AUTOSAR XML (schema 4-0-3)
package /ComponentTypes
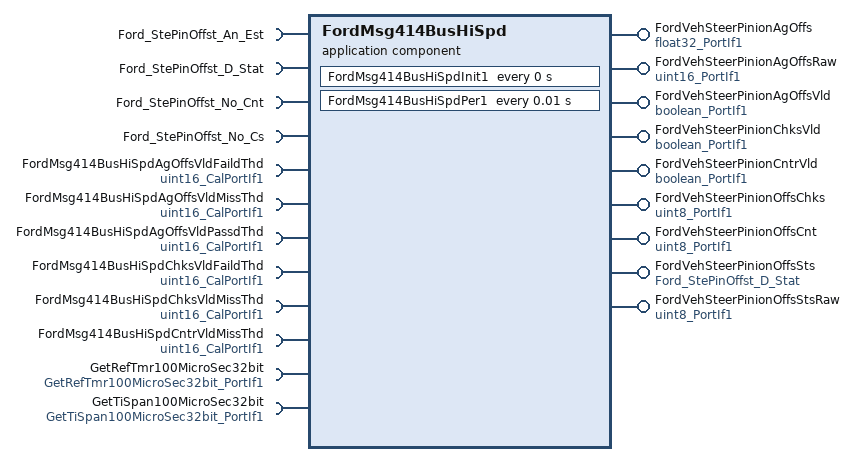
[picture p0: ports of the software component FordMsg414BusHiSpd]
  application sw component type FordMsg414BusHiSpd
    9 x provide port:
      FordVehSteerPinionAgOffs: nonqueued-sender-com-spec{data-element=Val, init-value=0}, provided-interface=float32_PortIf1
      FordVehSteerPinionAgOffsRaw: nonqueued-sender-com-spec{data-element=Val, init-value=32000}, provided-interface=uint16_PortIf1
      FordVehSteerPinionAgOffsVld: nonqueued-sender-com-spec{data-element=Logl, init-value=0}, provided-interface=boolean_PortIf1
      FordVehSteerPinionChksVld: nonqueued-sender-com-spec{data-element=Logl, init-value=0}, provided-interface=boolean_PortIf1
      FordVehSteerPinionCntrVld: nonqueued-sender-com-spec{data-element=Logl, init-value=0}, provided-interface=boolean_PortIf1
      FordVehSteerPinionOffsChks: nonqueued-sender-com-spec{data-element=Val, init-value=0}, provided-interface=uint8_PortIf1
      FordVehSteerPinionOffsCnt: nonqueued-sender-com-spec{data-element=Val, init-value=0}, provided-interface=uint8_PortIf1
      FordVehSteerPinionOffsSts: nonqueued-sender-com-spec{data-element=Ford_StePinOffst_D_Stat, init-value=0}, provided-interface=Ford_StePinOffst_D_Stat
      FordVehSteerPinionOffsStsRaw: nonqueued-sender-com-spec{data-element=Val, init-value=0}, provided-interface=uint8_PortIf1
    12 x require port:
      Ford_StePinOffst_An_Est: nonqueued-receiver-com-spec{data-element=Ford_StePinOffst_An_Est, filter=data-filter-type=ALWAYS, init-value=32000}, required-interface=Ford_StePinOffst_An_Est
      Ford_StePinOffst_D_Stat: nonqueued-receiver-com-spec{data-element=Ford_StePinOffst_D_Stat, filter=data-filter-type=ALWAYS, init-value=0}, required-interface=Ford_StePinOffst_D_Stat
      Ford_StePinOffst_No_Cnt: nonqueued-receiver-com-spec{data-element=Ford_StePinOffst_No_Cnt, filter=data-filter-type=ALWAYS, init-value=0}, required-interface=Ford_StePinOffst_No_Cnt
      Ford_StePinOffst_No_Cs: nonqueued-receiver-com-spec{data-element=Ford_StePinOffst_No_Cs, filter=data-filter-type=ALWAYS, init-value=0}, required-interface=Ford_StePinOffst_No_Cs
      FordMsg414BusHiSpdAgOffsVldFaildThd: parameter-require-com-spec{init-value=0, parameter=Val}, required-interface=uint16_CalPortIf1
      FordMsg414BusHiSpdAgOffsVldMissThd: parameter-require-com-spec{init-value=1000, parameter=Val}, required-interface=uint16_CalPortIf1
      FordMsg414BusHiSpdAgOffsVldPassdThd: parameter-require-com-spec{init-value=0, parameter=Val}, required-interface=uint16_CalPortIf1
      FordMsg414BusHiSpdChksVldFaildThd: parameter-require-com-spec{init-value=0, parameter=Val}, required-interface=uint16_CalPortIf1
      FordMsg414BusHiSpdChksVldMissThd: parameter-require-com-spec{init-value=0, parameter=Val}, required-interface=uint16_CalPortIf1
      FordMsg414BusHiSpdCntrVldMissThd: parameter-require-com-spec{init-value=0, parameter=Val}, required-interface=uint16_CalPortIf1
      GetRefTmr100MicroSec32bit: client-com-spec=Oper, required-interface=GetRefTmr100MicroSec32bit_PortIf1
      GetTiSpan100MicroSec32bit: client-com-spec=Oper, required-interface=GetTiSpan100MicroSec32bit_PortIf1
    behavior FordMsg414BusHiSpd_InternalBehavior
      ar-typed-per-instance-memorys:
        17 x data, all with sw-calibration-access=READ-ONLY:
          AgOffsVldFaildRefTi: type=uint32
          AgOffsVldMissRefTi: type=uint32
          AgOffsVldPassdRefTi: type=uint32
          ChksVldFaildRefTi: type=uint32
          ChksVldMissRefTi: type=uint32
          CntrVldMissRefTi: type=uint32
          FirstTranVldFlg: type=boolean
          FordVehMsg414Miss: type=boolean
          FordVehSteerPinionAgOffsPrev: type=float32
          FordVehSteerPinionAgOffsRawPrev: type=uint16
          FordVehSteerPinionAgOffsVldPrev: type=boolean
          FordVehSteerPinionChksVldPrev: type=boolean
          FordVehSteerPinionCntrVldPrev: type=boolean
          FordVehSteerPinionOffsChksPrev: type=uint8
          FordVehSteerPinionOffsCntPrev: type=uint8
          FordVehSteerPinionOffsStsPrev: type=Ford_StePinOffst_D_Stat
          FordVehSteerPinionOffsStsRawPrev: type=uint8
      timing event FordMsg414BusHiSpd_InitEvent: start-on-event=FordMsg414BusHiSpdInit1, period=0
      timing event TMT_FordMsg414BusHiSpdPer1: start-on-event=FordMsg414BusHiSpdPer1, period=0.01
      port-api-options:
        enable-take-address=false, indirect-api=false, port=Ford_StePinOffst_An_Est
        enable-take-address=false, indirect-api=false, port=Ford_StePinOffst_D_Stat
        enable-take-address=false, indirect-api=false, port=Ford_StePinOffst_No_Cnt
        enable-take-address=false, indirect-api=false, port=Ford_StePinOffst_No_Cs
        enable-take-address=false, indirect-api=false, port=FordMsg414BusHiSpdAgOffsVldFaildThd
        enable-take-address=false, indirect-api=false, port=FordMsg414BusHiSpdAgOffsVldMissThd
        enable-take-address=false, indirect-api=false, port=FordMsg414BusHiSpdAgOffsVldPassdThd
        enable-take-address=false, indirect-api=false, port=FordMsg414BusHiSpdChksVldFaildThd
        enable-take-address=false, indirect-api=false, port=FordVehSteerPinionAgOffs
        enable-take-address=false, indirect-api=false, port=FordVehSteerPinionAgOffsRaw
        enable-take-address=false, indirect-api=false, port=FordVehSteerPinionAgOffsVld
        enable-take-address=false, indirect-api=false, port=FordVehSteerPinionChksVld
        enable-take-address=false, indirect-api=false, port=FordVehSteerPinionCntrVld
        enable-take-address=false, indirect-api=false, port=FordVehSteerPinionOffsChks
        enable-take-address=false, indirect-api=false, port=FordVehSteerPinionOffsCnt
        enable-take-address=false, indirect-api=false, port=FordVehSteerPinionOffsSts
        enable-take-address=false, indirect-api=false, port=FordVehSteerPinionOffsStsRaw
        enable-take-address=false, indirect-api=false, port=GetRefTmr100MicroSec32bit
        enable-take-address=false, indirect-api=false, port=GetTiSpan100MicroSec32bit
      runnable FordMsg414BusHiSpdInit1
        sync call SC_GetRefTmr100MicroSec32bit_Oper: operation=GetRefTmr100MicroSec32bit.Oper, timeout=0
      runnable FordMsg414BusHiSpdPer1
        data-receive-point-by-arguments:
          4 x access:
            REC_Ford_StePinOffst_An_Est_Ford_StePinOffst_An_Est: accessed-variable=Ford_StePinOffst_An_Est.Ford_StePinOffst_An_Est
            REC_Ford_StePinOffst_D_Stat1_Ford_StePinOffst_D_Stat: accessed-variable=Ford_StePinOffst_D_Stat.Ford_StePinOffst_D_Stat
            REC_Ford_StePinOffst_No_Cnt_Ford_StePinOffst_No_Cnt: accessed-variable=Ford_StePinOffst_No_Cnt.Ford_StePinOffst_No_Cnt
            REC_Ford_StePinOffst_No_Cs_Ford_StePinOffst_No_Cs: accessed-variable=Ford_StePinOffst_No_Cs.Ford_StePinOffst_No_Cs
        data-send-points:
          9 x access:
            SEND_FordVehSteerPinionAgOffs_Val: accessed-variable=FordVehSteerPinionAgOffs.Val
            SEND_FordVehSteerPinionAgOffsRaw_Val: accessed-variable=FordVehSteerPinionAgOffsRaw.Val
            SEND_FordVehSteerPinionAgOffsVld_Logl: accessed-variable=FordVehSteerPinionAgOffsVld.Logl
            SEND_FordVehSteerPinionChksVld_Logl: accessed-variable=FordVehSteerPinionChksVld.Logl
            SEND_FordVehSteerPinionCntrVld_Logl: accessed-variable=FordVehSteerPinionCntrVld.Logl
            SEND_FordVehSteerPinionOffsChks_Val: accessed-variable=FordVehSteerPinionOffsChks.Val
            SEND_FordVehSteerPinionOffsCnt_Val: accessed-variable=FordVehSteerPinionOffsCnt.Val
            SEND_FordVehSteerPinionOffsSts_Ford_StePinOffst_D_Stat: accessed-variable=FordVehSteerPinionOffsSts.Ford_StePinOffst_D_Stat
            SEND_FordVehSteerPinionOffsStsRaw_Val: accessed-variable=FordVehSteerPinionOffsStsRaw.Val
        sync call SC_GetRefTmr100MicroSec32bit_Oper: operation=GetRefTmr100MicroSec32bit.Oper, timeout=0
        sync call SC_GetTiSpan100MicroSec32bit_Oper: operation=GetTiSpan100MicroSec32bit.Oper, timeout=0
  swc implementation FordMsg414BusHiSpd_Implementation: behavior=FordMsg414BusHiSpd_InternalBehavior
    code-descriptors:
      code Default: artifact-descriptors=autosar-engineering-object={short-label=Default, category=SWSRC}
